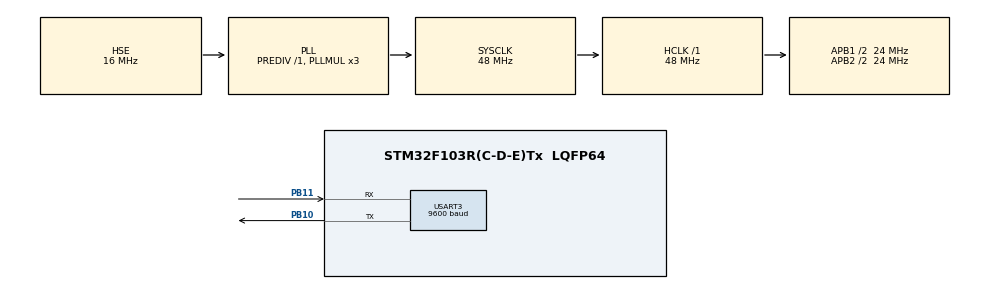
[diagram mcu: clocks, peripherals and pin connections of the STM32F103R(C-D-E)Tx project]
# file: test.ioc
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Mcu.Family=STM32F1
Mcu.Name=STM32F103R(C-D-E)Tx
Mcu.Package=LQFP64
NVIC.PriorityGroup=NVIC_PRIORITYGROUP_4
PA13.Mode=Serial_Wire
PA13.Signal=SYS_JTMS-SWDIO
PA14.Mode=Serial_Wire
PA14.Signal=SYS_JTCK-SWCLK
PB10.Mode=Asynchronous
PB10.Signal=USART3_TX
PB11.Mode=Asynchronous
PB11.Signal=USART3_RX
PD0-OSC_IN.Mode=HSE-External-Oscillator
PD0-OSC_IN.Signal=RCC_OSC_IN
PD1-OSC_OUT.Mode=HSE-External-Oscillator
PD1-OSC_OUT.Signal=RCC_OSC_OUT
ProjectManager.HeapSize=0x200
ProjectManager.StackSize=0x400
ProjectManager.TargetToolchain=SW4STM32
RCC.AHBFreq_Value=48000000
RCC.APB1CLKDivider=RCC_HCLK_DIV2
RCC.APB1Freq_Value=24000000
RCC.APB1TimFreq_Value=48000000
RCC.APB2CLKDivider=RCC_HCLK_DIV2
RCC.APB2Freq_Value=24000000
RCC.APB2TimFreq_Value=48000000
RCC.HCLKFreq_Value=48000000
RCC.HSE_VALUE=16000000
RCC.HSIState=RCC_HSI_ON
RCC.PLLMUL=RCC_PLL_MUL3
RCC.PLLSourceVirtual=RCC_PLLSOURCE_HSE
RCC.SYSCLKFreq_VALUE=48000000
RCC.SYSCLKSource=RCC_SYSCLKSOURCE_PLLCLK
RCC.USBFreq_Value=48000000
USART3.BaudRate=9600
board=test

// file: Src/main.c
/**
  ******************************************************************************
  * File Name          : main.c
  * Description        : Main program body
  ******************************************************************************
  *
  * COPYRIGHT(c) 2016 STMicroelectronics
  *
  * Redistribution and use in source and binary forms, with or without modification,
  * are permitted provided that the following conditions are met:
  *   1. Redistributions of source code must retain the above copyright notice,
  *      this list of conditions and the following disclaimer.
  *   2. Redistributions in binary form must reproduce the above copyright notice,
  *      this list of conditions and the following disclaimer in the documentation
  *      and/or other materials provided with the distribution.
  *   3. Neither the name of STMicroelectronics nor the names of its contributors
  *      may be used to endorse or promote products derived from this software
  *      without specific prior written permission.
  *
  * THIS SOFTWARE IS PROVIDED BY THE COPYRIGHT HOLDERS AND CONTRIBUTORS "AS IS"
  * AND ANY EXPRESS OR IMPLIED WARRANTIES, INCLUDING, BUT NOT LIMITED TO, THE
  * IMPLIED WARRANTIES OF MERCHANTABILITY AND FITNESS FOR A PARTICULAR PURPOSE ARE
  * DISCLAIMED. IN NO EVENT SHALL THE COPYRIGHT HOLDER OR CONTRIBUTORS BE LIABLE
  * FOR ANY DIRECT, INDIRECT, INCIDENTAL, SPECIAL, EXEMPLARY, OR CONSEQUENTIAL
  * DAMAGES (INCLUDING, BUT NOT LIMITED TO, PROCUREMENT OF SUBSTITUTE GOODS OR
  * SERVICES; LOSS OF USE, DATA, OR PROFITS; OR BUSINESS INTERRUPTION) HOWEVER
  * CAUSED AND ON ANY THEORY OF LIABILITY, WHETHER IN CONTRACT, STRICT LIABILITY,
  * OR TORT (INCLUDING NEGLIGENCE OR OTHERWISE) ARISING IN ANY WAY OUT OF THE USE
  * OF THIS SOFTWARE, EVEN IF ADVISED OF THE POSSIBILITY OF SUCH DAMAGE.
  *
  ******************************************************************************
  */
#include "main.h"
#include "stm32f1xx_hal.h"

UART_HandleTypeDef huart3;

/* USER CODE BEGIN PV */
/* Private variables ---------------------------------------------------------*/
uint8_t testo[8]={'1','2','3','4','5','6','\r','\n'};
uint32_t i;
/* USER CODE END PV */

void SystemClock_Config(void);
void Error_Handler(void);
static void MX_GPIO_Init(void);
static void MX_USART3_UART_Init(void);

/* USER CODE BEGIN PFP */
/* Private function prototypes -----------------------------------------------*/

/* USER CODE END PFP */

int main(void)
{

  /* MCU Configuration----------------------------------------------------------*/

  /* Reset of all peripherals, Initializes the Flash interface and the Systick. */
  HAL_Init();

  /* Configure the system clock */
  SystemClock_Config();

  /* Initialize all configured peripherals */
  MX_GPIO_Init();
  MX_USART3_UART_Init();

  /* Infinite loop */
  /* USER CODE BEGIN WHILE */
  while (1)
  {
HAL_UART_Transmit(&huart3, (uint8_t *)&testo, sizeof(testo), 1000000);
for (i=0;i<10000;i++);
  /* USER CODE END WHILE */

  }

}

/** System Clock Configuration
*/
void SystemClock_Config(void)
{

  RCC_OscInitTypeDef RCC_OscInitStruct;
  RCC_ClkInitTypeDef RCC_ClkInitStruct;

    /**Initializes the CPU, AHB and APB busses clocks
    */
  RCC_OscInitStruct.OscillatorType = RCC_OSCILLATORTYPE_HSE;
  RCC_OscInitStruct.HSEState = RCC_HSE_ON;
  RCC_OscInitStruct.HSEPredivValue = RCC_HSE_PREDIV_DIV1;
  RCC_OscInitStruct.HSIState = RCC_HSI_ON;
  RCC_OscInitStruct.PLL.PLLState = RCC_PLL_ON;
  RCC_OscInitStruct.PLL.PLLSource = RCC_PLLSOURCE_HSE;
  RCC_OscInitStruct.PLL.PLLMUL = RCC_PLL_MUL3;
  if (HAL_RCC_OscConfig(&RCC_OscInitStruct) != HAL_OK)
  {
    Error_Handler();
  }

    /**Initializes the CPU, AHB and APB busses clocks
    */
  RCC_ClkInitStruct.ClockType = RCC_CLOCKTYPE_HCLK|RCC_CLOCKTYPE_SYSCLK
                              |RCC_CLOCKTYPE_PCLK1|RCC_CLOCKTYPE_PCLK2;
  RCC_ClkInitStruct.SYSCLKSource = RCC_SYSCLKSOURCE_PLLCLK;
  RCC_ClkInitStruct.AHBCLKDivider = RCC_SYSCLK_DIV1;
  RCC_ClkInitStruct.APB1CLKDivider = RCC_HCLK_DIV2;
  RCC_ClkInitStruct.APB2CLKDivider = RCC_HCLK_DIV2;

  if (HAL_RCC_ClockConfig(&RCC_ClkInitStruct, FLASH_LATENCY_1) != HAL_OK)
  {
    Error_Handler();
  }

    /**Configure the Systick interrupt time
    */
  HAL_SYSTICK_Config(HAL_RCC_GetHCLKFreq()/1000);

    /**Configure the Systick
    */
  HAL_SYSTICK_CLKSourceConfig(SYSTICK_CLKSOURCE_HCLK);

  /* SysTick_IRQn interrupt configuration */
  HAL_NVIC_SetPriority(SysTick_IRQn, 0, 0);
}

/* USART3 init function */
static void MX_USART3_UART_Init(void)
{

  huart3.Instance = USART3;
  huart3.Init.BaudRate = 9600;
  huart3.Init.WordLength = UART_WORDLENGTH_8B;
  huart3.Init.StopBits = UART_STOPBITS_1;
  huart3.Init.Parity = UART_PARITY_NONE;
  huart3.Init.Mode = UART_MODE_TX_RX;
  huart3.Init.HwFlowCtl = UART_HWCONTROL_NONE;
  huart3.Init.OverSampling = UART_OVERSAMPLING_16;
  if (HAL_UART_Init(&huart3) != HAL_OK)
  {
    Error_Handler();
  }

}

/** Configure pins as
        * Analog
        * Input
        * Output
        * EVENT_OUT
        * EXTI
*/
static void MX_GPIO_Init(void)
{

  /* GPIO Ports Clock Enable */
  __HAL_RCC_GPIOD_CLK_ENABLE();
  __HAL_RCC_GPIOB_CLK_ENABLE();
  __HAL_RCC_GPIOA_CLK_ENABLE();

}

void Error_Handler(void)
{
  while(1)
  {
  }
}

/************************ (C) COPYRIGHT STMicroelectronics *****END OF FILE****/
